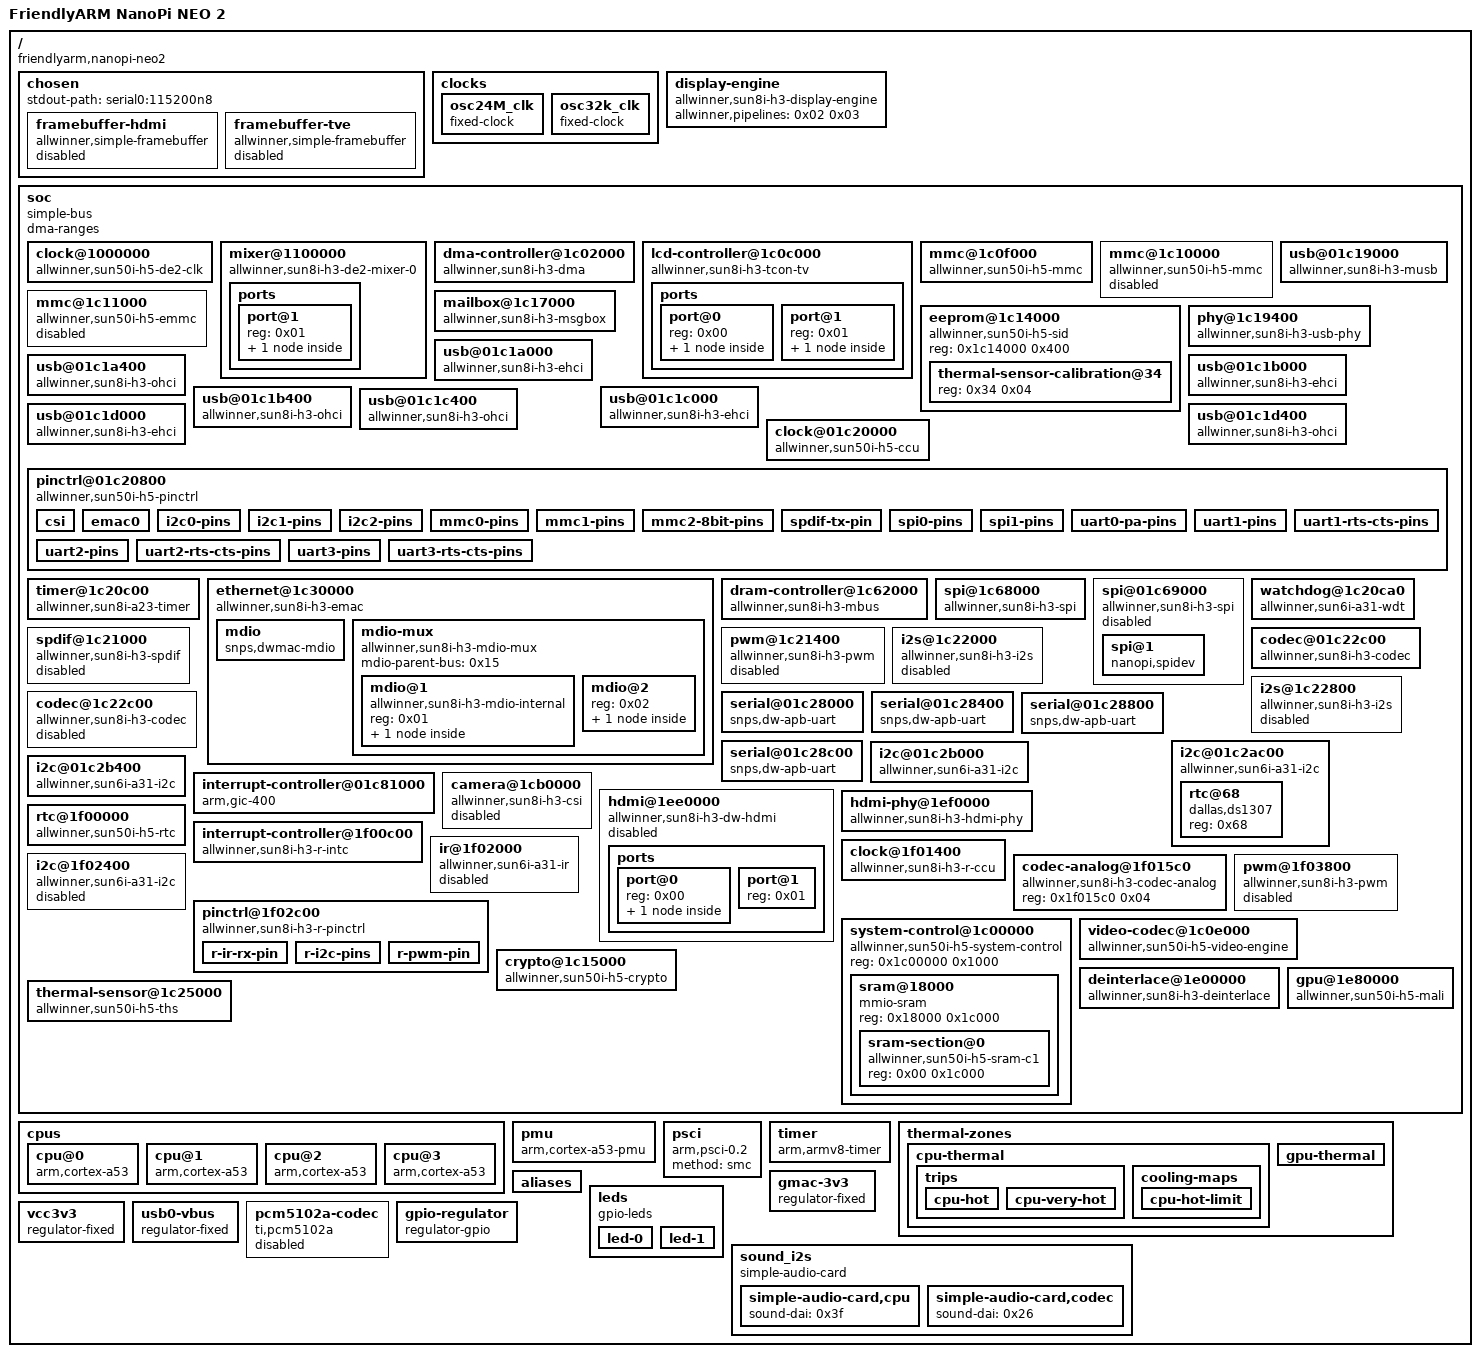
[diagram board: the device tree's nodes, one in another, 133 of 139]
/dts-v1/;

/ {
	interrupt-parent = <0x01>;
	#address-cells = <0x01>;
	#size-cells = <0x01>;
	model = "FriendlyARM NanoPi NEO 2";
	compatible = "friendlyarm,nanopi-neo2\0allwinner,sun50i-h5";

	chosen {
		#address-cells = <0x01>;
		#size-cells = <0x01>;
		ranges;
		stdout-path = "serial0:115200n8";

		framebuffer-hdmi {
			compatible = "allwinner,simple-framebuffer\0simple-framebuffer";
			allwinner,pipeline = "mixer0-lcd0-hdmi";
			clocks = <0x02 0x06 0x03 0x66 0x03 0x6f>;
			status = "disabled";
		};

		framebuffer-tve {
			compatible = "allwinner,simple-framebuffer\0simple-framebuffer";
			allwinner,pipeline = "mixer1-lcd1-tve";
			clocks = <0x02 0x07 0x03 0x67>;
			status = "disabled";
		};
	};

	clocks {
		#address-cells = <0x01>;
		#size-cells = <0x01>;
		ranges;

		osc24M_clk {
			#clock-cells = <0x00>;
			compatible = "fixed-clock";
			clock-frequency = <0x16e3600>;
			clock-accuracy = <0xc350>;
			clock-output-names = "osc24M";
			phandle = <0x0e>;
		};

		osc32k_clk {
			#clock-cells = <0x00>;
			compatible = "fixed-clock";
			clock-frequency = <0x8000>;
			clock-accuracy = <0xc350>;
			clock-output-names = "ext_osc32k";
			phandle = <0x21>;
		};
	};

	display-engine {
		compatible = "allwinner,sun8i-h3-display-engine";
		allwinner,pipelines = <0x02 0x03>;
		status = "okay";
		linux,phandle = <0x40>;
		phandle = <0x40>;
	};

	soc {
		compatible = "simple-bus";
		#address-cells = <0x01>;
		#size-cells = <0x01>;
		dma-ranges;
		ranges;

		clock@1000000 {
			reg = <0x1000000 0x10000>;
			clocks = <0x03 0x30 0x03 0x65>;
			clock-names = "bus\0mod";
			resets = <0x03 0x22>;
			#clock-cells = <0x01>;
			#reset-cells = <0x01>;
			compatible = "allwinner,sun50i-h5-de2-clk";
			phandle = <0x02>;
		};

		mixer@1100000 {
			compatible = "allwinner,sun8i-h3-de2-mixer-0";
			reg = <0x1100000 0x100000>;
			clocks = <0x02 0x00 0x02 0x06>;
			clock-names = "bus\0mod";
			resets = <0x02 0x00>;
			phandle = <0x04>;

			ports {
				#address-cells = <0x01>;
				#size-cells = <0x00>;

				port@1 {
					reg = <0x01>;

					endpoint {
						remote-endpoint = <0x05>;
						phandle = <0x06>;
					};
				};
			};
		};

		dma-controller@1c02000 {
			compatible = "allwinner,sun8i-h3-dma";
			reg = <0x1c02000 0x1000>;
			interrupts = <0x00 0x32 0x04>;
			clocks = <0x03 0x15>;
			resets = <0x03 0x06>;
			#dma-cells = <0x01>;
			phandle = <0x16>;
		};

		lcd-controller@1c0c000 {
			compatible = "allwinner,sun8i-h3-tcon-tv\0allwinner,sun8i-a83t-tcon-tv";
			reg = <0x1c0c000 0x1000>;
			interrupts = <0x00 0x56 0x04>;
			clocks = <0x03 0x2a 0x03 0x66>;
			clock-names = "ahb\0tcon-ch1";
			resets = <0x03 0x1b>;
			reset-names = "lcd";

			ports {
				#address-cells = <0x01>;
				#size-cells = <0x00>;

				port@0 {
					reg = <0x00>;

					endpoint {
						remote-endpoint = <0x06>;
						phandle = <0x05>;
					};
				};

				port@1 {
					#address-cells = <0x01>;
					#size-cells = <0x00>;
					reg = <0x01>;

					endpoint@1 {
						reg = <0x01>;
						remote-endpoint = <0x07>;
						phandle = <0x20>;
					};
				};
			};
		};

		mmc@1c0f000 {
			reg = <0x1c0f000 0x1000>;
			pinctrl-names = "default";
			pinctrl-0 = <0x08>;
			resets = <0x03 0x07>;
			reset-names = "ahb";
			interrupts = <0x00 0x3c 0x04>;
			status = "okay";
			#address-cells = <0x01>;
			#size-cells = <0x00>;
			compatible = "allwinner,sun50i-h5-mmc\0allwinner,sun50i-a64-mmc";
			clocks = <0x03 0x16 0x03 0x47>;
			clock-names = "ahb\0mmc";
			vmmc-supply = <0x09>;
			bus-width = <0x04>;
			cd-gpios = <0x0a 0x05 0x06 0x01>;
		};

		mmc@1c10000 {
			reg = <0x1c10000 0x1000>;
			pinctrl-names = "default";
			pinctrl-0 = <0x0b>;
			resets = <0x03 0x08>;
			reset-names = "ahb";
			interrupts = <0x00 0x3d 0x04>;
			status = "disabled";
			#address-cells = <0x01>;
			#size-cells = <0x00>;
			compatible = "allwinner,sun50i-h5-mmc\0allwinner,sun50i-a64-mmc";
			clocks = <0x03 0x17 0x03 0x4a>;
			clock-names = "ahb\0mmc";
		};

		mmc@1c11000 {
			reg = <0x1c11000 0x1000>;
			resets = <0x03 0x09>;
			reset-names = "ahb";
			interrupts = <0x00 0x3e 0x04>;
			status = "disabled";
			#address-cells = <0x01>;
			#size-cells = <0x00>;
			compatible = "allwinner,sun50i-h5-emmc\0allwinner,sun50i-a64-emmc";
			clocks = <0x03 0x18 0x03 0x4d>;
			clock-names = "ahb\0mmc";
		};

		eeprom@1c14000 {
			reg = <0x1c14000 0x400>;
			#address-cells = <0x01>;
			#size-cells = <0x01>;
			compatible = "allwinner,sun50i-h5-sid";

			thermal-sensor-calibration@34 {
				reg = <0x34 0x04>;
				phandle = <0x27>;
			};
		};

		mailbox@1c17000 {
			compatible = "allwinner,sun8i-h3-msgbox\0allwinner,sun6i-a31-msgbox";
			reg = <0x1c17000 0x1000>;
			clocks = <0x03 0x32>;
			resets = <0x03 0x24>;
			interrupts = <0x00 0x31 0x04>;
			#mbox-cells = <0x01>;
		};

		usb@01c19000 {
			compatible = "allwinner,sun8i-h3-musb";
			reg = <0x1c19000 0x400>;
			clocks = <0x04 0x20>;
			resets = <0x04 0x11>;
			interrupts = <0x00 0x47 0x04>;
			interrupt-names = "mc";
			phys = <0x18 0x00>;
			phy-names = "usb";
			extcon = <0x18 0x00>;
			status = "okay";
			dr_mode = "otg";
			linux,phandle = <0x4f>;
			phandle = <0x4f>;
		};

		phy@1c19400 {
			compatible = "allwinner,sun8i-h3-usb-phy";
			reg = <0x1c19400 0x2c 0x1c1a800 0x04 0x1c1b800 0x04 0x1c1c800 0x04 0x1c1d800 0x04>;
			reg-names = "phy_ctrl\0pmu0\0pmu1\0pmu2\0pmu3";
			clocks = <0x03 0x58 0x03 0x59 0x03 0x5a 0x03 0x5b>;
			clock-names = "usb0_phy\0usb1_phy\0usb2_phy\0usb3_phy";
			resets = <0x03 0x00 0x03 0x01 0x03 0x02 0x03 0x03>;
			reset-names = "usb0_reset\0usb1_reset\0usb2_reset\0usb3_reset";
			status = "okay";
			#phy-cells = <0x01>;
			usb0_id_det-gpios = <0x0a 0x06 0x0c 0x00>;
			usb0_vbus-supply = <0x0d>;
			phandle = <0x0c>;
		};

		usb@01c1a000 {
			compatible = "allwinner,sun8i-h3-ehci\0generic-ehci";
			reg = <0x1c1a000 0x100>;
			interrupts = <0x00 0x48 0x04>;
			clocks = <0x04 0x21 0x04 0x25>;
			resets = <0x04 0x12 0x04 0x16>;
			status = "okay";
			linux,phandle = <0x51>;
			phandle = <0x51>;
		};

		usb@01c1a400 {
			compatible = "allwinner,sun8i-h3-ohci\0generic-ohci";
			reg = <0x1c1a400 0x100>;
			interrupts = <0x00 0x49 0x04>;
			clocks = <0x04 0x21 0x04 0x25 0x04 0x5c>;
			resets = <0x04 0x12 0x04 0x16>;
			status = "okay";
			linux,phandle = <0x52>;
			phandle = <0x52>;
		};

		usb@01c1b000 {
			compatible = "allwinner,sun8i-h3-ehci\0generic-ehci";
			reg = <0x1c1b000 0x100>;
			interrupts = <0x00 0x4a 0x04>;
			clocks = <0x04 0x22 0x04 0x26>;
			resets = <0x04 0x13 0x04 0x17>;
			phys = <0x18 0x01>;
			phy-names = "usb";
			status = "okay";
			linux,phandle = <0x53>;
			phandle = <0x53>;
		};

		usb@01c1b400 {
			compatible = "allwinner,sun8i-h3-ohci\0generic-ohci";
			reg = <0x1c1b400 0x100>;
			interrupts = <0x00 0x4b 0x04>;
			clocks = <0x04 0x22 0x04 0x26 0x04 0x5d>;
			resets = <0x04 0x13 0x04 0x17>;
			phys = <0x18 0x01>;
			phy-names = "usb";
			status = "okay";
			linux,phandle = <0x54>;
			phandle = <0x54>;
		};

		usb@01c1c000 {
			compatible = "allwinner,sun8i-h3-ehci\0generic-ehci";
			reg = <0x1c1c000 0x100>;
			interrupts = <0x00 0x4c 0x04>;
			clocks = <0x04 0x23 0x04 0x27>;
			resets = <0x04 0x14 0x04 0x18>;
			phys = <0x18 0x02>;
			phy-names = "usb";
			status = "okay";
			linux,phandle = <0x55>;
			phandle = <0x55>;
		};

		usb@01c1c400 {
			compatible = "allwinner,sun8i-h3-ohci\0generic-ohci";
			reg = <0x1c1c400 0x100>;
			interrupts = <0x00 0x4d 0x04>;
			clocks = <0x04 0x23 0x04 0x27 0x04 0x5e>;
			resets = <0x04 0x14 0x04 0x18>;
			phys = <0x18 0x02>;
			phy-names = "usb";
			status = "okay";
			linux,phandle = <0x56>;
			phandle = <0x56>;
		};

		usb@01c1d000 {
			compatible = "allwinner,sun8i-h3-ehci\0generic-ehci";
			reg = <0x1c1d000 0x100>;
			interrupts = <0x00 0x4e 0x04>;
			clocks = <0x04 0x24 0x04 0x28>;
			resets = <0x04 0x15 0x04 0x19>;
			phys = <0x18 0x03>;
			phy-names = "usb";
			status = "okay";
			linux,phandle = <0x57>;
			phandle = <0x57>;
		};

		usb@01c1d400 {
			compatible = "allwinner,sun8i-h3-ohci\0generic-ohci";
			reg = <0x1c1d400 0x100>;
			interrupts = <0x00 0x4f 0x04>;
			clocks = <0x04 0x24 0x04 0x28 0x04 0x5f>;
			resets = <0x04 0x15 0x04 0x19>;
			phys = <0x18 0x03>;
			phy-names = "usb";
			status = "okay";
			linux,phandle = <0x58>;
			phandle = <0x58>;
		};

		clock@01c20000 {
			reg = <0x1c20000 0x400>;
			clocks = <0x1a 0x1b>;
			clock-names = "hosc\0losc";
			#clock-cells = <0x01>;
			#reset-cells = <0x01>;
			compatible = "allwinner,sun50i-h5-ccu";
			linux,phandle = <0x04>;
			phandle = <0x04>;
		};

		pinctrl@01c20800 {
			reg = <0x1c20800 0x400>;
			interrupts = <0x00 0x0b 0x04 0x00 0x11 0x04 0x00 0x17 0x04>;
			clocks = <0x04 0x36 0x1a 0x1b>;
			clock-names = "apb\0hosc\0losc";
			gpio-controller;
			#gpio-cells = <0x03>;
			interrupt-controller;
			#interrupt-cells = <0x03>;
			compatible = "allwinner,sun50i-h5-pinctrl";
			linux,phandle = <0x17>;
			phandle = <0x17>;

			csi {
				pins = "PE0\0PE1\0PE2\0PE3\0PE4\0PE5\0PE6\0PE7\0PE8\0PE9\0PE10\0PE11";
				function = "csi";
				linux,phandle = <0x2f>;
				phandle = <0x2f>;
			};

			emac0 {
				pins = "PD0\0PD1\0PD2\0PD3\0PD4\0PD5\0PD7\0PD8\0PD9\0PD10\0PD12\0PD13\0PD15\0PD16\0PD17";
				function = "emac";
				drive-strength = <0x28>;
				linux,phandle = <0x1d>;
				phandle = <0x1d>;
			};

			i2c0-pins {
				pins = "PA11\0PA12";
				function = "i2c0";
				phandle = <0x1b>;
			};

			i2c1-pins {
				pins = "PA18\0PA19";
				function = "i2c1";
				phandle = <0x1c>;
			};

			i2c2-pins {
				pins = "PE12\0PE13";
				function = "i2c2";
				phandle = <0x1d>;
			};

			mmc0-pins {
				pins = "PF0\0PF1\0PF2\0PF3\0PF4\0PF5";
				function = "mmc0";
				drive-strength = <0x1e>;
				bias-pull-up;
				phandle = <0x08>;
			};

			mmc1-pins {
				pins = "PG0\0PG1\0PG2\0PG3\0PG4\0PG5";
				function = "mmc1";
				drive-strength = <0x1e>;
				bias-pull-up;
				phandle = <0x0b>;
			};

			mmc2-8bit-pins {
				pins = "PC5\0PC6\0PC8\0PC9\0PC10\0PC11\0PC12\0PC13\0PC14\0PC15\0PC16";
				function = "mmc2";
				drive-strength = <0x1e>;
				bias-pull-up;
			};

			spdif-tx-pin {
				pins = "PA17";
				function = "spdif";
			};

			spi0-pins {
				pins = "PC0\0PC1\0PC2\0PC3";
				function = "spi0";
				phandle = <0x17>;
			};

			spi1-pins {
				pins = "PA15\0PA16\0PA14\0PA13";
				function = "spi1";
				phandle = <0x18>;
			};

			uart0-pa-pins {
				pins = "PA4\0PA5";
				function = "uart0";
				phandle = <0x1a>;
			};

			uart1-pins {
				pins = "PG6\0PG7";
				function = "uart1";
			};

			uart1-rts-cts-pins {
				pins = "PG8\0PG9";
				function = "uart1";
			};

			uart2-pins {
				pins = "PA0\0PA1";
				function = "uart2";
			};

			uart2-rts-cts-pins {
				pins = "PA2\0PA3";
				function = "uart2";
			};

			uart3-pins {
				pins = "PA13\0PA14";
				function = "uart3";
			};

			uart3-rts-cts-pins {
				pins = "PA15\0PA16";
				function = "uart3";
			};
		};

		timer@1c20c00 {
			compatible = "allwinner,sun8i-a23-timer";
			reg = <0x1c20c00 0xa0>;
			interrupts = <0x00 0x12 0x04 0x00 0x13 0x04>;
			clocks = <0x0e>;
		};

		ethernet@1c30000 {
			compatible = "allwinner,sun8i-h3-emac";
			syscon = <0x11>;
			reg = <0x1c30000 0x10000>;
			interrupts = <0x00 0x52 0x04>;
			interrupt-names = "macirq";
			resets = <0x03 0x0c>;
			reset-names = "stmmaceth";
			clocks = <0x03 0x1b>;
			clock-names = "stmmaceth";
			status = "okay";
			pinctrl-names = "default";
			pinctrl-0 = <0x12>;
			phy-supply = <0x13>;
			phy-handle = <0x14>;
			phy-mode = "rgmii-id";

			mdio {
				#address-cells = <0x01>;
				#size-cells = <0x00>;
				compatible = "snps,dwmac-mdio";
				phandle = <0x15>;
			};

			mdio-mux {
				compatible = "allwinner,sun8i-h3-mdio-mux";
				#address-cells = <0x01>;
				#size-cells = <0x00>;
				mdio-parent-bus = <0x15>;

				mdio@1 {
					compatible = "allwinner,sun8i-h3-mdio-internal";
					reg = <0x01>;
					#address-cells = <0x01>;
					#size-cells = <0x00>;

					ethernet-phy@1 {
						compatible = "ethernet-phy-ieee802.3-c22";
						reg = <0x01>;
						clocks = <0x03 0x43>;
						resets = <0x03 0x27>;
					};
				};

				mdio@2 {
					reg = <0x02>;
					#address-cells = <0x01>;
					#size-cells = <0x00>;

					ethernet-phy@7 {
						compatible = "ethernet-phy-ieee802.3-c22";
						reg = <0x07>;
						phandle = <0x14>;
					};
				};
			};
		};

		dram-controller@1c62000 {
			compatible = "allwinner,sun8i-h3-mbus";
			reg = <0x1c62000 0x1000>;
			clocks = <0x03 0x71>;
			#address-cells = <0x01>;
			#size-cells = <0x01>;
			dma-ranges = <0x00 0x40000000 0xc0000000>;
			#interconnect-cells = <0x01>;
			phandle = <0x26>;
		};

		spi@1c68000 {
			compatible = "allwinner,sun8i-h3-spi";
			reg = <0x1c68000 0x1000>;
			interrupts = <0x00 0x41 0x04>;
			clocks = <0x04 0x1e 0x04 0x52>;
			clock-names = "ahb\0mod";
			dmas = <0x07 0x17 0x07 0x17>;
			dma-names = "rx\0tx";
			pinctrl-names = "default";
			pinctrl-0 = <0x20 0x21>;
			resets = <0x04 0x0f>;
			status = "okay";
			#address-cells = <0x01>;
			#size-cells = <0x00>;
		};

		spi@01c69000 {
			compatible = "allwinner,sun8i-h3-spi";
			reg = <0x1c69000 0x1000>;
			interrupts = <0x00 0x42 0x04>;
			clocks = <0x04 0x1f 0x04 0x53>;
			clock-names = "ahb\0mod";
			dmas = <0x07 0x18 0x07 0x18>;
			dma-names = "rx\0tx";
			pinctrl-names = "default";
			pinctrl-0 = <0x22>;
			resets = <0x04 0x10>;
			status = "disable";
			#address-cells = <0x01>;
			#size-cells = <0x00>;
			linux,phandle = <0x66>;
			phandle = <0x66>;

			spi@1 {
				compatible = "nanopi,spidev";
				reg = <0x00>;
				spi-max-frequency = <0x989680>;
				linux,phandle = <0x67>;
				phandle = <0x67>;
			};
		};

		watchdog@1c20ca0 {
			compatible = "allwinner,sun6i-a31-wdt";
			reg = <0x1c20ca0 0x20>;
			interrupts = <0x00 0x19 0x04>;
			clocks = <0x0e>;
		};

		spdif@1c21000 {
			#sound-dai-cells = <0x00>;
			compatible = "allwinner,sun8i-h3-spdif";
			reg = <0x1c21000 0x400>;
			interrupts = <0x00 0x0c 0x04>;
			clocks = <0x03 0x35 0x03 0x57>;
			resets = <0x03 0x29>;
			clock-names = "apb\0spdif";
			dmas = <0x16 0x02>;
			dma-names = "tx";
			status = "disabled";
			linux,phandle = <0x69>;
			phandle = <0x69>;
		};

		pwm@1c21400 {
			compatible = "allwinner,sun8i-h3-pwm";
			reg = <0x1c21400 0x08>;
			clocks = <0x0e>;
			#pwm-cells = <0x03>;
			status = "disabled";
		};

		i2s@1c22000 {
			#sound-dai-cells = <0x00>;
			compatible = "allwinner,sun8i-h3-i2s";
			reg = <0x1c22000 0x400>;
			interrupts = <0x00 0x0d 0x04>;
			clocks = <0x03 0x38 0x03 0x54>;
			clock-names = "apb\0mod";
			dmas = <0x16 0x03 0x16 0x03>;
			resets = <0x03 0x2b>;
			dma-names = "rx\0tx";
			status = "disabled";
		};

		codec@01c22c00 {
			#sound-dai-cells = <0x00>;
			compatible = "allwinner,sun8i-h3-codec";
			reg = <0x1c22c00 0x400>;
			interrupts = <0x00 0x1d 0x04>;
			clocks = <0x04 0x34 0x04 0x6d>;
			clock-names = "apb\0codec";
			resets = <0x04 0x28>;
			dmas = <0x07 0x0f 0x07 0x0f>;
			dma-names = "rx\0tx";
			allwinner,codec-analog-controls = <0x24>;
			status = "okay";
			allwinner,audio-routing = "Line Out\0LINEOUT\0MIC1\0Mic\0Mic\0MBIAS";
			linux,phandle = <0x6b>;
			phandle = <0x6b>;
		};

		i2s@1c22800 {
			#sound-dai-cells = <0x00>;
			compatible = "allwinner,sun8i-h3-i2s";
			reg = <0x1c22800 0x400>;
			interrupts = <0x00 0x0f 0x04>;
			clocks = <0x03 0x3a 0x03 0x56>;
			clock-names = "apb\0mod";
			dmas = <0x16 0x1b>;
			resets = <0x03 0x2d>;
			dma-names = "tx";
			status = "disabled";
		};

		codec@1c22c00 {
			#sound-dai-cells = <0x00>;
			compatible = "allwinner,sun8i-h3-codec";
			reg = <0x1c22c00 0x400>;
			interrupts = <0x00 0x1d 0x04>;
			clocks = <0x03 0x34 0x03 0x6d>;
			clock-names = "apb\0codec";
			resets = <0x03 0x28>;
			dmas = <0x16 0x0f 0x16 0x0f>;
			dma-names = "rx\0tx";
			allwinner,codec-analog-controls = <0x19>;
			status = "disabled";
		};

		serial@01c28000 {
			compatible = "snps,dw-apb-uart";
			reg = <0x1c28000 0x400>;
			interrupts = <0x00 0x00 0x04>;
			reg-shift = <0x02>;
			reg-io-width = <0x04>;
			clocks = <0x04 0x3e>;
			resets = <0x04 0x31>;
			dmas = <0x07 0x06 0x07 0x06>;
			dma-names = "rx\0tx";
			status = "okay";
			pinctrl-names = "default";
			pinctrl-0 = <0x27>;
			linux,phandle = <0x6c>;
			phandle = <0x6c>;
		};

		serial@01c28400 {
			compatible = "snps,dw-apb-uart";
			reg = <0x1c28400 0x400>;
			interrupts = <0x00 0x01 0x04>;
			reg-shift = <0x02>;
			reg-io-width = <0x04>;
			clocks = <0x04 0x3f>;
			resets = <0x04 0x32>;
			dmas = <0x07 0x07 0x07 0x07>;
			dma-names = "rx\0tx";
			status = "okay";
			pinctrl-names = "default";
			pinctrl-0 = <0x28>;
			linux,phandle = <0x6d>;
			phandle = <0x6d>;
		};

		serial@01c28800 {
			compatible = "snps,dw-apb-uart";
			reg = <0x1c28800 0x400>;
			interrupts = <0x00 0x02 0x04>;
			reg-shift = <0x02>;
			reg-io-width = <0x04>;
			clocks = <0x04 0x40>;
			resets = <0x04 0x33>;
			dmas = <0x07 0x08 0x07 0x08>;
			dma-names = "rx\0tx";
			status = "okay";
			pinctrl-names = "default";
			pinctrl-0 = <0x29>;
			linux,phandle = <0x6e>;
			phandle = <0x6e>;
		};

		serial@01c28c00 {
			compatible = "snps,dw-apb-uart";
			reg = <0x1c28c00 0x400>;
			interrupts = <0x00 0x03 0x04>;
			reg-shift = <0x02>;
			reg-io-width = <0x04>;
			clocks = <0x04 0x41>;
			resets = <0x04 0x34>;
			dmas = <0x07 0x09 0x07 0x09>;
			dma-names = "rx\0tx";
			status = "okay";
			pinctrl-names = "default";
			pinctrl-0 = <0x2a 0x2b>;
			linux,phandle = <0x6f>;
			phandle = <0x6f>;
		};

		i2c@01c2ac00 {
			compatible = "allwinner,sun6i-a31-i2c";
			reg = <0x1c2ac00 0x400>;
			interrupts = <0x00 0x06 0x04>;
			clocks = <0x04 0x3b>;
			resets = <0x04 0x2e>;
			pinctrl-names = "default";
			pinctrl-0 = <0x2c>;
			status = "okay";
			#address-cells = <0x01>;
			#size-cells = <0x00>;
			linux,phandle = <0x70>;
			phandle = <0x70>;

			rtc@68 {
				compatible = "dallas,ds1307";
				reg = <0x68>;
			};
		};

		i2c@01c2b000 {
			compatible = "allwinner,sun6i-a31-i2c";
			reg = <0x1c2b000 0x400>;
			interrupts = <0x00 0x07 0x04>;
			clocks = <0x04 0x3c>;
			resets = <0x04 0x2f>;
			pinctrl-names = "default";
			pinctrl-0 = <0x2d>;
			status = "okay";
			#address-cells = <0x01>;
			#size-cells = <0x00>;
			linux,phandle = <0x71>;
			phandle = <0x71>;
		};

		i2c@01c2b400 {
			compatible = "allwinner,sun6i-a31-i2c";
			reg = <0x1c2b400 0x400>;
			interrupts = <0x00 0x08 0x04>;
			clocks = <0x04 0x3d>;
			resets = <0x04 0x30>;
			pinctrl-names = "default";
			pinctrl-0 = <0x2e>;
			status = "okay";
			#address-cells = <0x01>;
			#size-cells = <0x00>;
			linux,phandle = <0x72>;
			phandle = <0x72>;
		};

		interrupt-controller@01c81000 {
			compatible = "arm,gic-400";
			reg = <0x1c81000 0x1000 0x1c82000 0x2000 0x1c84000 0x2000 0x1c86000 0x2000>;
			interrupt-controller;
			#interrupt-cells = <0x03>;
			interrupts = <0x01 0x09 0xf04>;
			linux,phandle = <0x01>;
			phandle = <0x01>;
		};

		camera@1cb0000 {
			compatible = "allwinner,sun8i-h3-csi";
			reg = <0x1cb0000 0x1000>;
			interrupts = <0x00 0x54 0x04>;
			clocks = <0x03 0x2d 0x03 0x6a 0x03 0x62>;
			clock-names = "bus\0mod\0ram";
			resets = <0x03 0x1e>;
			pinctrl-names = "default";
			pinctrl-0 = <0x1e>;
			status = "disabled";
		};

		hdmi@1ee0000 {
			compatible = "allwinner,sun8i-h3-dw-hdmi\0allwinner,sun8i-a83t-dw-hdmi";
			reg = <0x1ee0000 0x10000>;
			reg-io-width = <0x01>;
			interrupts = <0x00 0x58 0x04>;
			clocks = <0x03 0x2f 0x03 0x70 0x03 0x6f>;
			clock-names = "iahb\0isfr\0tmds";
			resets = <0x03 0x21>;
			reset-names = "ctrl";
			phys = <0x1f>;
			phy-names = "phy";
			status = "disabled";

			ports {
				#address-cells = <0x01>;
				#size-cells = <0x00>;

				port@0 {
					reg = <0x00>;

					endpoint {
						remote-endpoint = <0x20>;
						phandle = <0x07>;
					};
				};

				port@1 {
					reg = <0x01>;
				};
			};
		};

		hdmi-phy@1ef0000 {
			compatible = "allwinner,sun8i-h3-hdmi-phy";
			reg = <0x1ef0000 0x10000>;
			clocks = <0x03 0x2f 0x03 0x70 0x03 0x06>;
			clock-names = "bus\0mod\0pll-0";
			resets = <0x03 0x20>;
			reset-names = "phy";
			#phy-cells = <0x00>;
			phandle = <0x1f>;
		};

		rtc@1f00000 {
			reg = <0x1f00000 0x400>;
			interrupt-parent = <0x10>;
			interrupts = <0x00 0x28 0x04 0x00 0x29 0x04>;
			clock-output-names = "osc32k\0osc32k-out\0iosc";
			clocks = <0x21>;
			#clock-cells = <0x01>;
			compatible = "allwinner,sun50i-h5-rtc";
			phandle = <0x0f>;
		};

		interrupt-controller@1f00c00 {
			compatible = "allwinner,sun8i-h3-r-intc\0allwinner,sun6i-a31-r-intc";
			interrupt-controller;
			#interrupt-cells = <0x03>;
			reg = <0x1f00c00 0x400>;
			interrupts = <0x00 0x20 0x04>;
			phandle = <0x10>;
		};

		clock@1f01400 {
			compatible = "allwinner,sun8i-h3-r-ccu";
			reg = <0x1f01400 0x100>;
			clocks = <0x0e 0x0f 0x00 0x0f 0x02 0x03 0x09>;
			clock-names = "hosc\0losc\0iosc\0pll-periph";
			#clock-cells = <0x01>;
			#reset-cells = <0x01>;
			phandle = <0x22>;
		};

		codec-analog@1f015c0 {
			compatible = "allwinner,sun8i-h3-codec-analog";
			reg = <0x1f015c0 0x04>;
			phandle = <0x19>;
		};

		ir@1f02000 {
			compatible = "allwinner,sun6i-a31-ir";
			clocks = <0x22 0x04 0x22 0x0b>;
			clock-names = "apb\0ir";
			resets = <0x22 0x00>;
			interrupts = <0x00 0x25 0x04>;
			reg = <0x1f02000 0x400>;
			status = "disabled";
		};

		i2c@1f02400 {
			compatible = "allwinner,sun6i-a31-i2c";
			reg = <0x1f02400 0x400>;
			interrupts = <0x00 0x2c 0x04>;
			pinctrl-names = "default";
			pinctrl-0 = <0x23>;
			clocks = <0x22 0x09>;
			resets = <0x22 0x05>;
			status = "disabled";
			#address-cells = <0x01>;
			#size-cells = <0x00>;
		};

		pinctrl@1f02c00 {
			compatible = "allwinner,sun8i-h3-r-pinctrl";
			reg = <0x1f02c00 0x400>;
			interrupt-parent = <0x10>;
			interrupts = <0x00 0x2d 0x04>;
			clocks = <0x22 0x03 0x0e 0x0f 0x00>;
			clock-names = "apb\0hosc\0losc";
			gpio-controller;
			#gpio-cells = <0x03>;
			interrupt-controller;
			#interrupt-cells = <0x03>;
			phandle = <0x2e>;

			r-ir-rx-pin {
				pins = "PL11";
				function = "s_cir_rx";
			};

			r-i2c-pins {
				pins = "PL0\0PL1";
				function = "s_i2c";
				phandle = <0x23>;
			};

			r-pwm-pin {
				pins = "PL10";
				function = "s_pwm";
				phandle = <0x24>;
			};
		};

		pwm@1f03800 {
			compatible = "allwinner,sun8i-h3-pwm";
			reg = <0x1f03800 0x08>;
			pinctrl-names = "default";
			pinctrl-0 = <0x24>;
			clocks = <0x0e>;
			#pwm-cells = <0x03>;
			status = "disabled";
		};

		system-control@1c00000 {
			compatible = "allwinner,sun50i-h5-system-control";
			reg = <0x1c00000 0x1000>;
			#address-cells = <0x01>;
			#size-cells = <0x01>;
			ranges;
			phandle = <0x11>;

			sram@18000 {
				compatible = "mmio-sram";
				reg = <0x18000 0x1c000>;
				#address-cells = <0x01>;
				#size-cells = <0x01>;
				ranges = <0x00 0x18000 0x1c000>;

				sram-section@0 {
					compatible = "allwinner,sun50i-h5-sram-c1\0allwinner,sun4i-a10-sram-c1";
					reg = <0x00 0x1c000>;
					phandle = <0x25>;
				};
			};
		};

		video-codec@1c0e000 {
			compatible = "allwinner,sun50i-h5-video-engine";
			reg = <0x1c0e000 0x1000>;
			clocks = <0x03 0x29 0x03 0x6c 0x03 0x61>;
			clock-names = "ahb\0mod\0ram";
			resets = <0x03 0x1a>;
			interrupts = <0x00 0x3a 0x04>;
			allwinner,sram = <0x25 0x01>;
		};

		crypto@1c15000 {
			compatible = "allwinner,sun50i-h5-crypto";
			reg = <0x1c15000 0x1000>;
			interrupts = <0x00 0x5e 0x04>;
			clocks = <0x03 0x14 0x03 0x51>;
			clock-names = "bus\0mod";
			resets = <0x03 0x05>;
		};

		deinterlace@1e00000 {
			compatible = "allwinner,sun8i-h3-deinterlace";
			reg = <0x1e00000 0x20000>;
			clocks = <0x03 0x2c 0x03 0x68 0x03 0x63>;
			clock-names = "bus\0mod\0ram";
			resets = <0x03 0x1d>;
			interrupts = <0x00 0x5d 0x04>;
			interconnects = <0x26 0x09>;
			interconnect-names = "dma-mem";
		};

		gpu@1e80000 {
			compatible = "allwinner,sun50i-h5-mali\0arm,mali-450";
			reg = <0x1e80000 0x30000>;
			interrupts = <0x00 0x60 0x04 0x00 0x61 0x04 0x00 0x63 0x04 0x00 0x64 0x04 0x00 0x65 0x04 0x00 0x66 0x04 0x00 0x67 0x04 0x00 0x68 0x04 0x00 0x69 0x04 0x00 0x6a 0x04 0x00 0x6b 0x04>;
			interrupt-names = "gp\0gpmmu\0pp\0pp0\0ppmmu0\0pp1\0ppmmu1\0pp2\0ppmmu2\0pp3\0ppmmu3";
			clocks = <0x03 0x31 0x03 0x72>;
			clock-names = "bus\0core";
			resets = <0x03 0x23>;
			assigned-clocks = <0x03 0x72>;
			assigned-clock-rates = <0x16e36000>;
		};

		thermal-sensor@1c25000 {
			compatible = "allwinner,sun50i-h5-ths";
			reg = <0x1c25000 0x400>;
			interrupts = <0x00 0x1f 0x04>;
			resets = <0x03 0x2a>;
			clocks = <0x03 0x37 0x03 0x45>;
			clock-names = "bus\0mod";
			nvmem-cells = <0x27>;
			nvmem-cell-names = "calibration";
			#thermal-sensor-cells = <0x01>;
			phandle = <0x2c>;
		};
	};

	cpus {
		#address-cells = <0x01>;
		#size-cells = <0x00>;

		cpu@0 {
			compatible = "arm,cortex-a53";
			device_type = "cpu";
			reg = <0x00>;
			enable-method = "psci";
			clocks = <0x03 0x0e>;
			clock-latency-ns = <0x3b9b0>;
			#cooling-cells = <0x02>;
			phandle = <0x28>;
		};

		cpu@1 {
			compatible = "arm,cortex-a53";
			device_type = "cpu";
			reg = <0x01>;
			enable-method = "psci";
			clocks = <0x03 0x0e>;
			clock-latency-ns = <0x3b9b0>;
			#cooling-cells = <0x02>;
			phandle = <0x29>;
		};

		cpu@2 {
			compatible = "arm,cortex-a53";
			device_type = "cpu";
			reg = <0x02>;
			enable-method = "psci";
			clocks = <0x03 0x0e>;
			clock-latency-ns = <0x3b9b0>;
			#cooling-cells = <0x02>;
			phandle = <0x2a>;
		};

		cpu@3 {
			compatible = "arm,cortex-a53";
			device_type = "cpu";
			reg = <0x03>;
			enable-method = "psci";
			clocks = <0x03 0x0e>;
			clock-latency-ns = <0x3b9b0>;
			#cooling-cells = <0x02>;
			phandle = <0x2b>;
		};
	};

	pmu {
		compatible = "arm,cortex-a53-pmu";
		interrupts = <0x00 0x74 0x04 0x00 0x75 0x04 0x00 0x76 0x04 0x00 0x77 0x04>;
		interrupt-affinity = <0x28 0x29 0x2a 0x2b>;
	};

	psci {
		compatible = "arm,psci-0.2";
		method = "smc";
	};

	timer {
		compatible = "arm,armv8-timer";
		arm,no-tick-in-suspend;
		interrupts = <0x01 0x0d 0xf08 0x01 0x0e 0xf08 0x01 0x0b 0xf08 0x01 0x0a 0xf08>;
	};

	thermal-zones {

		cpu-thermal {
			polling-delay-passive = <0x00>;
			polling-delay = <0x00>;
			thermal-sensors = <0x2c 0x00>;

			trips {

				cpu-hot {
					temperature = <0x13880>;
					hysteresis = <0x7d0>;
					type = "passive";
					phandle = <0x2d>;
				};

				cpu-very-hot {
					temperature = <0x186a0>;
					hysteresis = <0x00>;
					type = "critical";
				};
			};

			cooling-maps {

				cpu-hot-limit {
					trip = <0x2d>;
					cooling-device = <0x28 0xffffffff 0xffffffff 0x29 0xffffffff 0xffffffff 0x2a 0xffffffff 0xffffffff 0x2b 0xffffffff 0xffffffff>;
				};
			};
		};

		gpu-thermal {
			polling-delay-passive = <0x00>;
			polling-delay = <0x00>;
			thermal-sensors = <0x2c 0x01>;
		};
	};

	aliases {
		ethernet0 = "/soc/ethernet@1c30000";
		serial0 = "/soc/serial@1c28000";
	};

	leds {
		compatible = "gpio-leds";

		led-0 {
			label = "nanopi:green:pwr";
			gpios = <0x2e 0x00 0x0a 0x00>;
			default-state = "on";
		};

		led-1 {
			label = "nanopi:blue:status";
			gpios = <0x0a 0x00 0x0a 0x00>;
		};
	};

	gmac-3v3 {
		compatible = "regulator-fixed";
		regulator-name = "gmac-3v3";
		regulator-min-microvolt = <0x325aa0>;
		regulator-max-microvolt = <0x325aa0>;
		startup-delay-us = <0x186a0>;
		enable-active-high;
		gpio = <0x0a 0x03 0x06 0x00>;
		phandle = <0x13>;
	};

	vcc3v3 {
		compatible = "regulator-fixed";
		regulator-name = "vcc3v3";
		regulator-min-microvolt = <0x325aa0>;
		regulator-max-microvolt = <0x325aa0>;
		linux,phandle = <0x16>;
		phandle = <0x16>;
	};

	usb0-vbus {
		compatible = "regulator-fixed";
		regulator-name = "usb0-vbus";
		regulator-min-microvolt = <0x4c4b40>;
		regulator-max-microvolt = <0x4c4b40>;
		enable-active-high;
		gpio = <0x3e 0x00 0x02 0x00>;
		status = "okay";
		linux,phandle = <0x19>;
		phandle = <0x19>;
	};

	pcm5102a-codec {
		#sound-dai-cells = <0x00>;
		compatible = "ti,pcm5102a";
		status = "disabled";
		linux,phandle = <0x26>;
		phandle = <0x26>;
	};

	sound_i2s {
		compatible = "simple-audio-card";
		simple-audio-card,name = "I2S-master";
		simple-audio-card,mclk-fs = <0x100>;
		simple-audio-card,format = "i2s";
		status = "okay";

		simple-audio-card,cpu {
			sound-dai = <0x3f>;
		};

		simple-audio-card,codec {
			sound-dai = <0x26>;
		};
	};

	gpio-regulator {
		compatible = "regulator-gpio";
		regulator-name = "vdd-cpux";
		regulator-type = "voltage";
		regulator-boot-on;
		regulator-always-on;
		regulator-min-microvolt = <0x10c8e0>;
		regulator-max-microvolt = <0x10c8e0>;
		regulator-ramp-delay = <0x32>;
		gpios = <0x3e 0x00 0x06 0x00>;
		gpios-states = <0x01>;
		states = <0x10c8e0 0x00 0x10c8e0 0x01>;
		linux,phandle = <0x3a>;
		phandle = <0x3a>;
	};

	__symbols__ {
		osc24M = "/clocks/osc24M_clk";
		osc32k = "/clocks/osc32k_clk";
		iosc = "/clocks/internal-osc-clk";
		de = "/display-engine";
		display_clocks = "/soc/clock@1000000";
		hdmi = "/soc/hdmi@1ee0000";
		hdmi_in = "/soc/hdmi@1ee0000/ports/port@0";
		hdmi_in_tcon0 = "/soc/hdmi@1ee0000/ports/port@0/endpoint@0";
		hdmi_out = "/soc/hdmi@1ee0000/ports/port@1";
		hdmi_out_con = "/soc/hdmi@1ee0000/ports/port@1/endpoint";
		i2s2 = "/soc/i2s@1c22800";
		mixer0 = "/soc/mixer@1100000";
		mixer0_out = "/soc/mixer@1100000/ports/port@1";
		mixer0_out_tcon0 = "/soc/mixer@1100000/ports/port@1/endpoint@0";
		mixer0_out_tcon1 = "/soc/mixer@1100000/ports/port@1/endpoint@1";
		mixer1 = "/soc/mixer@1200000";
		mixer1_out = "/soc/mixer@1200000/ports/port@1";
		mixer1_out_tcon0 = "/soc/mixer@1200000/ports/port@1/endpoint@0";
		mixer1_out_tcon1 = "/soc/mixer@1200000/ports/port@1/endpoint@1";
		sound_hdmi = "/soc/sound";
		tcon0 = "/soc/lcd-controller@1c0c000";
		tcon0_in = "/soc/lcd-controller@1c0c000/ports/port@0";
		tcon0_in_mixer0 = "/soc/lcd-controller@1c0c000/ports/port@0/endpoint@0";
		tcon0_in_mixer1 = "/soc/lcd-controller@1c0c000/ports/port@0/endpoint@1";
		tcon0_out = "/soc/lcd-controller@1c0c000/ports/port@1";
		tcon0_out_hdmi = "/soc/lcd-controller@1c0c000/ports/port@1/endpoint@1";
		tcon1 = "/soc/lcd-controller@1c0d000";
		tcon1_in = "/soc/lcd-controller@1c0d000/ports/port@0";
		tcon1_in_mixer0 = "/soc/lcd-controller@1c0d000/ports/port@0/endpoint@0";
		tcon1_in_mixer1 = "/soc/lcd-controller@1c0d000/ports/port@0/endpoint@1";
		tcon1_out = "/soc/lcd-controller@1c0d000/ports/port@1";
		syscon = "/soc/syscon@1c00000";
		dma = "/soc/dma-controller@01c02000";
		mmc0 = "/soc/mmc@01c0f000";
		mmc1 = "/soc/mmc@01c10000";
		mmc2 = "/soc/mmc@01c11000";
		usb_otg = "/soc/usb@01c19000";
		sid = "/soc/eeprom@01c14000";
		usbphy = "/soc/phy@01c19400";
		ehci0 = "/soc/usb@01c1a000";
		ohci0 = "/soc/usb@01c1a400";
		ehci1 = "/soc/usb@01c1b000";
		ohci1 = "/soc/usb@01c1b400";
		ehci2 = "/soc/usb@01c1c000";
		ohci2 = "/soc/usb@01c1c400";
		ehci3 = "/soc/usb@01c1d000";
		ohci3 = "/soc/usb@01c1d400";
		ccu = "/soc/clock@01c20000";
		pio = "/soc/pinctrl@01c20800";
		csi_pins = "/soc/pinctrl@01c20800/csi";
		emac_rgmii_pins = "/soc/pinctrl@01c20800/emac0";
		i2s0_pins = "/soc/pinctrl@01c20800/i2s0";
		i2c0_pins = "/soc/pinctrl@01c20800/i2c0";
		i2c1_pins = "/soc/pinctrl@01c20800/i2c1";
		i2c2_pins = "/soc/pinctrl@01c20800/i2c2";
		mmc0_pins_a = "/soc/pinctrl@01c20800/mmc0@0";
		mmc0_cd_pin = "/soc/pinctrl@01c20800/mmc0_cd_pin@0";
		mmc1_pins_a = "/soc/pinctrl@01c20800/mmc1@0";
		mmc2_8bit_pins = "/soc/pinctrl@01c20800/mmc2_8bit";
		spdif_tx_pins_a = "/soc/pinctrl@01c20800/spdif@0";
		spi0_pins = "/soc/pinctrl@01c20800/spi0";
		spi1_pins = "/soc/pinctrl@01c20800/spi1";
		uart0_pins_a = "/soc/pinctrl@01c20800/uart0@0";
		uart1_pins = "/soc/pinctrl@01c20800/uart1";
		uart1_rts_cts_pins = "/soc/pinctrl@01c20800/uart1_rts_cts";
		uart2_pins = "/soc/pinctrl@01c20800/uart2";
		uart2_rts_cts_pins = "/soc/pinctrl@01c20800/uart2_rts_cts";
		uart3_pins = "/soc/pinctrl@01c20800/uart3";
		uart3_rts_cts_pins = "/soc/pinctrl@01c20800/uart3_rts_cts";
		pwm0_pins = "/soc/pinctrl@01c20800/pwm0";
		leds_npi = "/soc/pinctrl@01c20800/led_pins@0";
		spi0_cs_pins = "/soc/pinctrl@01c20800/spi0_cs_pins";
		ths = "/soc/ths@01c25000";
		emac = "/soc/ethernet@1c30000";
		mdio = "/soc/ethernet@1c30000/mdio";
		ext_rgmii_phy = "/soc/ethernet@1c30000/mdio/ethernet-phy@1";
		int_mii_phy = "/soc/ethernet@1c30000/mdio/ethernet-phy@1";
		spi0 = "/soc/spi@01c68000";
		spidev0 = "/soc/spi@01c68000/spi@0";
		spiflash = "/soc/spi@01c68000/spiflash@0";
		spioled = "/soc/spi@01c68000/spioled@0";
		pitft = "/soc/spi@01c68000/pitft@0";
		pitft_ts = "/soc/spi@01c68000/pitft-ts@1";
		spi1 = "/soc/spi@01c69000";
		spidev1 = "/soc/spi@01c69000/spi@1";
		wdt0 = "/soc/watchdog@01c20ca0";
		spdif = "/soc/spdif@01c21000";
		pwm = "/soc/pwm@01c21400";
		codec = "/soc/codec@01c22c00";
		i2s0 = "/soc/i2s@01c22000";
		uart0 = "/soc/serial@01c28000";
		uart1 = "/soc/serial@01c28400";
		uart2 = "/soc/serial@01c28800";
		uart3 = "/soc/serial@01c28c00";
		i2c0 = "/soc/i2c@01c2ac00";
		i2c1 = "/soc/i2c@01c2b000";
		i2c2 = "/soc/i2c@01c2b400";
		gic = "/soc/interrupt-controller@01c81000";
		csi = "/soc/camera@01cb0000";
		rtc = "/soc/rtc@01f00000";
		r_ccu = "/soc/clock@1f01400";
		codec_analog = "/soc/codec-analog@01f015c0";
		ir = "/soc/ir@01f02000";
		r_i2c = "/soc/i2c@01f02400";
		r_pio = "/soc/pinctrl@01f02c00";
		ir_pins_a = "/soc/pinctrl@01f02c00/ir@0";
		r_i2c_pins_a = "/soc/pinctrl@01f02c00/r_i2c@0";
		leds_r_npi = "/soc/pinctrl@01f02c00/led_pins@0";
		cpu_thermal = "/thermal-zones/cpu_thermal";
		cpu_warm = "/thermal-zones/cpu_thermal/trips/cpu_warm";
		cpu_hot = "/thermal-zones/cpu_thermal/trips/cpu_hot";
		cpu_very_hot = "/thermal-zones/cpu_thermal/trips/cpu_very_hot";
		cpu_alert_hot = "/thermal-zones/cpu_thermal/trips/cpu_alert_hot";
		cpu_crit = "/thermal-zones/cpu_thermal/trips/cpu_crit";
		cpu0 = "/cpus/cpu@0";
		hdmi_con_in = "/connector/port/endpoint";
		reg_gmac_3v3 = "/gmac-3v3";
		reg_vcc3v3 = "/vcc3v3";
		reg_usb0_vbus = "/usb0-vbus";
		pcm5102a = "/pcm5102a-codec";
		vdd_cpux = "/gpio-regulator";
	};
};
